# BlockD: IP-XACT component
VLNV example.org:FutureLib:BlockD:1.0

## Address spaces and blocks
BlockDMap.SubBlockA: base 0x0000, range 0x100, width 32
BlockDMap.SubBlockB: base 0x0100, range 0x100, width 32

## Registers
Registers are 32-bit, read-write, no defined reset value unless marked. A register's access mark holds for its fields unless they carry their own. Offsets are from the block's base; lines under a group give offsets from that group; [hi:lo] are bit positions; {n}, {i} and the like mark numbered series; 'fields as' and 'values as' point back to an identical list; <NAME> marks a mode.

## BlockDMap.SubBlockA
Base 0x00000000
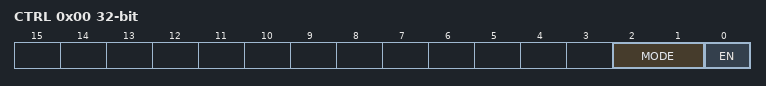
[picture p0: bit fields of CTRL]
0x00 CTRL
  [2:1] MODE, [0] EN

## BlockDMap.SubBlockB
Base 0x00000100
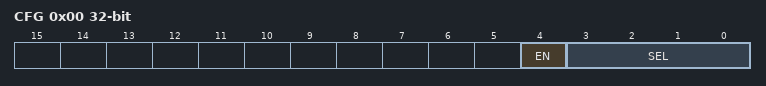
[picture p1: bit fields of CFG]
0x00 CFG
  [4] EN, [3:0] SEL
